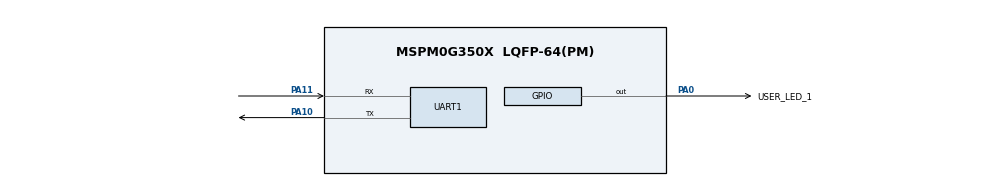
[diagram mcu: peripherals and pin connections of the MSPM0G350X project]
/**
 * @cliArgs --device "MSPM0G350X" --part "Default" --package "LQFP-64(PM)" --product "mspm0_sdk@2.05.01.00"
 * @versions {"tool":"1.24.0+4110"}
 */

/**
 * Import the modules used in this configuration.
 */
const ADC12         = scripting.addModule("/ti/driverlib/ADC12", {}, false);
const ADC121        = ADC12.addInstance();
const AES           = scripting.addModule("/ti/driverlib/AES");
const GPIO          = scripting.addModule("/ti/driverlib/GPIO", {}, false);
const GPIO1         = GPIO.addInstance();
const MATHACL       = scripting.addModule("/ti/driverlib/MATHACL");
const SYSCTL        = scripting.addModule("/ti/driverlib/SYSCTL");
const TIMER         = scripting.addModule("/ti/driverlib/TIMER", {}, false);
const TIMER1        = TIMER.addInstance();
const UART          = scripting.addModule("/ti/driverlib/UART", {}, false);
const UART1         = UART.addInstance();
const VREF          = scripting.addModule("/ti/driverlib/VREF");
const WWDT          = scripting.addModule("/ti/driverlib/WWDT", {}, false);
const WWDT1         = WWDT.addInstance();
const ProjectConfig = scripting.addModule("/ti/project_config/ProjectConfig");

/**
 * Write custom configuration values to the imported modules.
 */
ADC121.$name                          = "ADC12_0";
ADC121.trigSrc                        = "DL_ADC12_TRIG_SRC_EVENT";
ADC121.subChanID                      = 1;
ADC121.configureDMA                   = true;
ADC121.adcMem0vref                    = "VREF";
ADC121.sampleTime0                    = "13 us";
ADC121.enabledDMATriggers             = ["DL_ADC12_DMA_MEM0_RESULT_LOADED"];
ADC121.sampCnt                        = 10;
ADC121.adcPin0Config.$name            = "ti_driverlib_gpio_GPIOPinGeneric0";
ADC121.DMA_CHANNEL.$name              = "DMA_CH0";
ADC121.DMA_CHANNEL.peripheral.$assign = "DMA_CH0";

const Board = scripting.addModule("/ti/driverlib/Board", {}, false);

GPIO1.$name                          = "GPIO_LEDS";
GPIO1.associatedPins[0].$name        = "USER_LED_1";
GPIO1.associatedPins[0].assignedPin  = "0";
GPIO1.associatedPins[0].initialValue = "SET";
GPIO1.associatedPins[0].pin.$assign  = "PA0";

SYSCTL.clockTreeEn = true;

TIMER1.$name                       = "TIMER_0";
TIMER1.timerMode                   = "PERIODIC_UP";
TIMER1.event1PublisherChannel      = 1;
TIMER1.event1ControllerInterruptEn = ["ZERO_EVENT"];

UART1.$name                    = "UART_0";
UART1.targetBaudRate           = 115200;
UART1.peripheral.rxPin.$assign = "PA11";
UART1.peripheral.txPin.$assign = "PA10";
UART1.txPinConfig.$name        = "ti_driverlib_gpio_GPIOPinGeneric2";
UART1.rxPinConfig.$name        = "ti_driverlib_gpio_GPIOPinGeneric3";

VREF.vrefPosPinConfig.$name = "ti_driverlib_gpio_GPIOPinGeneric1";

WWDT1.$name        = "WWDT0";
WWDT1.clockDivider = "8";

ProjectConfig.genDisable = true;

/**
 * Pinmux solution for unlocked pins/peripherals. This ensures that minor changes to the automatic solver in a future
 * version of the tool will not impact the pinmux you originally saw.  These lines can be completely deleted in order to
 * re-solve from scratch.
 */
ADC121.peripheral.$suggestSolution          = "ADC1";
ADC121.peripheral.adcPin0.$suggestSolution  = "PA15";
Board.peripheral.$suggestSolution           = "DEBUGSS";
Board.peripheral.swclkPin.$suggestSolution  = "PA20";
Board.peripheral.swdioPin.$suggestSolution  = "PA19";
TIMER1.peripheral.$suggestSolution          = "TIMA0";
UART1.peripheral.$suggestSolution           = "UART0";
VREF.peripheral.$suggestSolution            = "VREF";
VREF.peripheral.vrefPosPin.$suggestSolution = "PA23";
WWDT1.peripheral.$suggestSolution           = "WWDT0";
